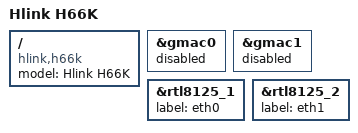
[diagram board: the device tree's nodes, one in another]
// SPDX-License-Identifier: (GPL-2.0+ OR MIT)
// Copyright (c) 2022 AmadeusGhost <amadeus@jmu.edu.cn>
// Copyright (c) 2022 Flippy <flippy@sina.com>

/dts-v1/;

#include "rk3568-hlink-h68k.dts"

/ {
	model = "Hlink H66K";
	compatible = "hlink,h66k", "rockchip,rk3568";
};

&gmac0 {
	status = "disabled";
};

&gmac1 {
	status = "disabled";
};

/*
&gic {
	mbi-ranges = <105 20>, <202 56>, <264 56>;
};
*/

&rtl8125_1 {
	label = "eth0";
};

&rtl8125_2 {
	label = "eth1";
};
